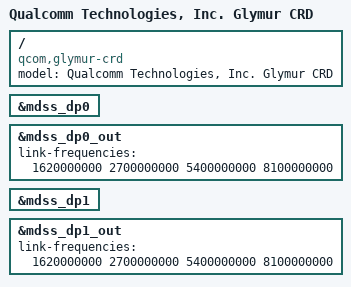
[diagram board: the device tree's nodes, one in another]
// SPDX-License-Identifier: BSD-3-Clause
/*
 * Copyright (c) Qualcomm Technologies, Inc. and/or its subsidiaries.
 */

/dts-v1/;

#include "glymur.dtsi"
#include "glymur-crd.dtsi"

/ {
	model = "Qualcomm Technologies, Inc. Glymur CRD";
	compatible = "qcom,glymur-crd", "qcom,glymur";
};

&mdss_dp0 {
	status = "okay";
};

&mdss_dp0_out {
	link-frequencies = /bits/ 64 <1620000000 2700000000 5400000000 8100000000>;
};

&mdss_dp1 {
	status = "okay";
};

&mdss_dp1_out {
	link-frequencies = /bits/ 64 <1620000000 2700000000 5400000000 8100000000>;
};
